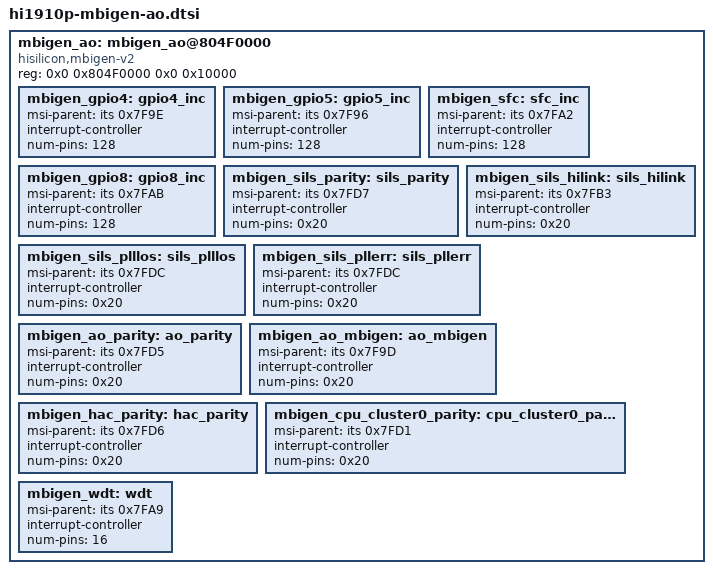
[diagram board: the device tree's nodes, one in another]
/**
* dts file for Hisilicon Ascend Dxxx Development Board
*
* Copyright (C) 2020 Hisilicon Ltd.
*
* This program is free software; you can redistribute it and/or modify
* it under the terms of the GNU General Public License version 2 as
* publishhed by the Free Software Foundation.
*
* Owner：OS
* Author:  c00283067
* Create: Tue Apr 21 20:07:41 EDT 2020
*/
    mbigen_ao: mbigen_ao@804F0000 {
        compatible = "hisilicon,mbigen-v2";
        reg = <0x0 0x804F0000 0x0 0x10000>;
        mbigen_gpio4: gpio4_inc {
            msi-parent = <&its 0x7F9E>;
            interrupt-controller;
            #interrupt-cells = <0x2>;
            num-pins = <128>;
        };
        mbigen_gpio5: gpio5_inc {
            msi-parent = <&its 0x7F96>;
            interrupt-controller;
            #interrupt-cells = <0x2>;
            num-pins = <128>;
        };
        mbigen_sfc: sfc_inc {
            msi-parent = <&its 0x7FA2>;
            interrupt-controller;
            #interrupt-cells = <0x2>;
            num-pins = <128>;
        };
        mbigen_gpio8: gpio8_inc {
            msi-parent = <&its 0x7FAB>;
            interrupt-controller;
            #interrupt-cells = <0x2>;
            num-pins = <128>;
        };
        mbigen_sils_parity: sils_parity {
            msi-parent = <&its 0x7FD7>;
            interrupt-controller;
            #interrupt-cells = <0x2>;
            num-pins = <0x20>;
        };
        mbigen_sils_hilink: sils_hilink {
            msi-parent = <&its 0x7FB3>;
            interrupt-controller;
            #interrupt-cells = <0x2>;
            num-pins = <0x20>;
        };
        mbigen_sils_plllos: sils_plllos {
            msi-parent = <&its 0x7FDC>;
            interrupt-controller;
            #interrupt-cells = <0x2>;
            num-pins = <0x20>;
        };
        mbigen_sils_pllerr: sils_pllerr {
            msi-parent = <&its 0x7FDC>;
            interrupt-controller;
            #interrupt-cells = <0x2>;
            num-pins = <0x20>;
        };
        mbigen_ao_parity: ao_parity {
            msi-parent = <&its 0x7FD5>;
            interrupt-controller;
            #interrupt-cells = <0x2>;
            num-pins = <0x20>;
        };
        mbigen_ao_mbigen: ao_mbigen {
            msi-parent = <&its 0x7F9D>;
            interrupt-controller;
            #interrupt-cells = <0x2>;
            num-pins = <0x20>;
        };
        mbigen_hac_parity: hac_parity {
            msi-parent = <&its 0x7FD6>;
            interrupt-controller;
            #interrupt-cells = <0x2>;
            num-pins = <0x20>;
        };
        mbigen_cpu_cluster0_parity: cpu_cluster0_parity {
            msi-parent = <&its 0x7FD1>;
            interrupt-controller;
            #interrupt-cells = <0x2>;
            num-pins = <0x20>;
        };
        mbigen_wdt: wdt {
            msi-parent = <&its 0x7FA9>;
            interrupt-controller;
            #interrupt-cells = <0x2>;
            num-pins = <16>;
        };
    };
